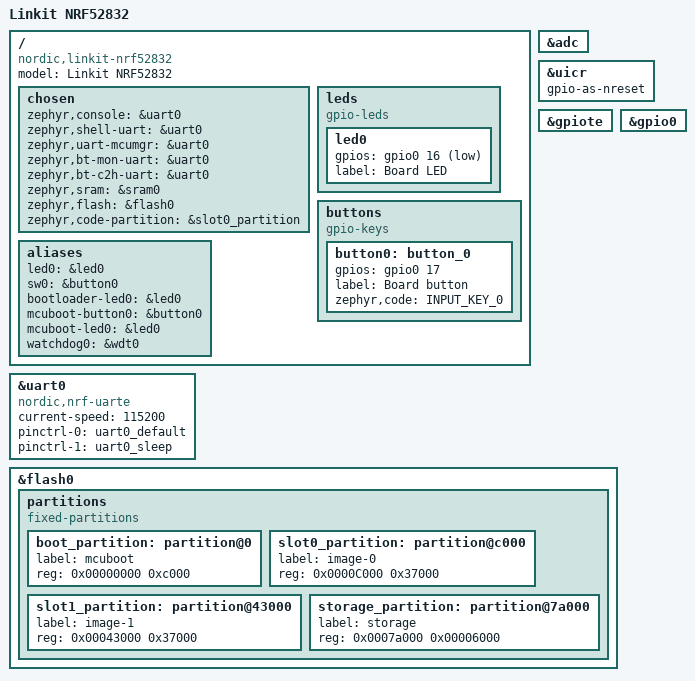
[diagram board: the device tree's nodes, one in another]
/*
 * Copyright (c) 2017 Shawn Nock <shawn@monadnock.ca>
 * Copyright (c) 2017 Linaro Limited
 *
 * SPDX-License-Identifier: Apache-2.0
 */

/dts-v1/;
#include <nordic/nrf52832_qfaa.dtsi>
#include "linkit_nrf52832-pinctrl.dtsi"
#include <zephyr/dt-bindings/input/input-event-codes.h>

/ {
	model = "Linkit NRF52832";
	compatible = "nordic,linkit-nrf52832";

	chosen {
		zephyr,console = &uart0;
		zephyr,shell-uart = &uart0;
		zephyr,uart-mcumgr = &uart0;
		zephyr,bt-mon-uart = &uart0;
		zephyr,bt-c2h-uart = &uart0;
		zephyr,sram = &sram0;
		zephyr,flash = &flash0;
		zephyr,code-partition = &slot0_partition;
	};

	leds {
		compatible = "gpio-leds";
        led0: led0 {
			gpios = < &gpio0 16 GPIO_ACTIVE_LOW >;
			label = "Board LED";
		};
	};

	buttons {
		compatible = "gpio-keys";
		button0: button_0 {
			gpios = < &gpio0 17 GPIO_ACTIVE_HIGH >;
			label = "Board button";
            zephyr,code = <INPUT_KEY_0>;
		};
	};

	/* These aliases are provided for compatibility with samples */
	aliases {
		led0 = &led0;
		sw0 = &button0;
		bootloader-led0 = &led0;
		mcuboot-button0 = &button0;
		mcuboot-led0 = &led0;
		watchdog0 = &wdt0;
	};
};

&uart0 {
	status = "okay";
	compatible = "nordic,nrf-uarte";
	current-speed = <115200>;
	pinctrl-0 = <&uart0_default>;
	pinctrl-1 = <&uart0_sleep>;
	pinctrl-names = "default", "sleep";
};

&adc {
	status = "okay";
};

&uicr {
	gpio-as-nreset;
};

&gpiote {
	status = "okay";
};

&gpio0 {
	status = "okay";
};

&flash0 {

	partitions {
		compatible = "fixed-partitions";
		#address-cells = <1>;
		#size-cells = <1>;

		boot_partition: partition@0 {
			label = "mcuboot";
			reg = <0x00000000 0xc000>;
		};
		slot0_partition: partition@c000 {
			label = "image-0";
			reg = <0x0000C000 0x37000>;
		};
		slot1_partition: partition@43000 {
			label = "image-1";
			reg = <0x00043000 0x37000>;
		};
		storage_partition: partition@7a000 {
			label = "storage";
			reg = <0x0007a000 0x00006000>;
		};
	};
};
